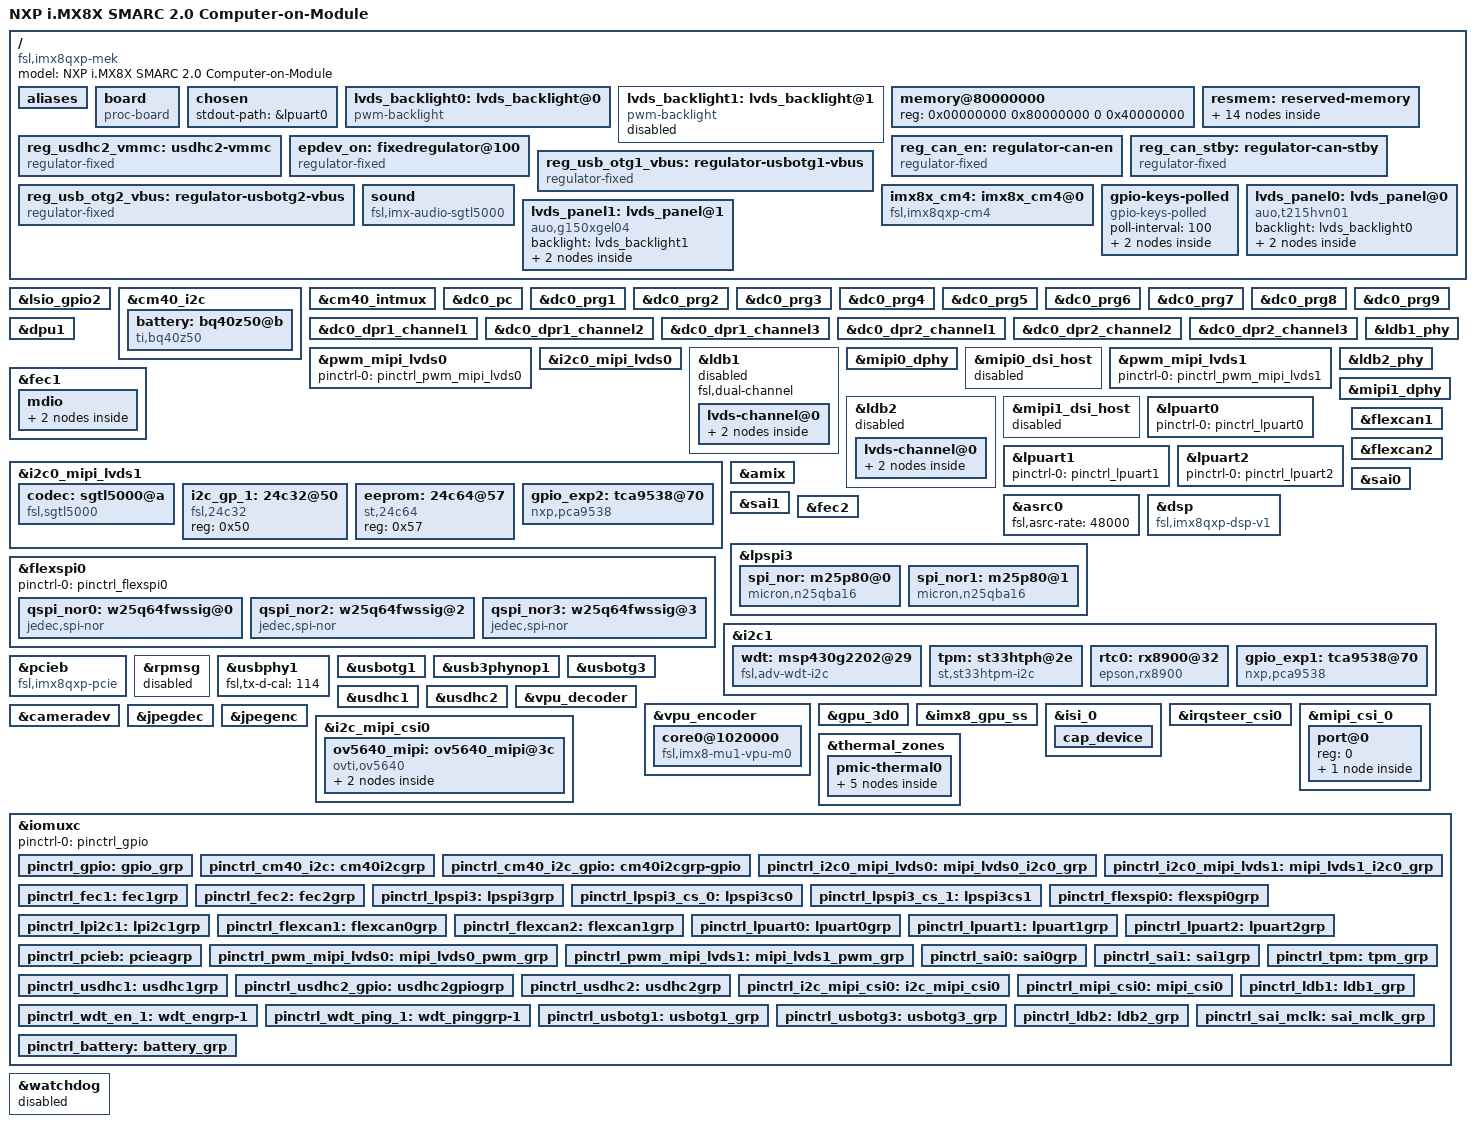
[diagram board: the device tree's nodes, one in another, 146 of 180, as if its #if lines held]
// SPDX-License-Identifier: GPL-2.0+
/*
 * Copyright 2017-2020 Advantech
 */

/dts-v1/;

#include "imx8qxp.dtsi"
#include <dt-bindings/usb/pd.h>

/* Definitions */
#define ROM_DB5901
#define SDHC_LOW_SPEED_ONLY
#define ROM_DB5901_I2S_CN3

/* LVDS Panel : only choose one!
 *   LVDS_AUO_7, LVDS_CHIMEI_15, LVDS_AUO_215
 */
#define LVDS_AUO_7

#ifdef LVDS_AUO_215
  #define LVDS_DUAL_CHANNEL
#endif
/*************************** based on imx8x-mek.dtsi *****************************/

/ {
	model = "NXP i.MX8X SMARC 2.0 Computer-on-Module";
	compatible = "fsl,imx8qxp-mek", "fsl,imx8qxp";

	aliases {
		rtc0 = &rtc0;
		rtc1 = &rtc;
	};

	board {
		compatible = "proc-board";
		board-type = "ROM-5620 A1";
		board-cpu = "IMX8X";
	};

	aliases {
		i2c0 = &i2c_mipi_csi0;
		i2c1 = &cm40_i2c;
		i2c2 = &i2c0_mipi_lvds0;
		i2c3 = &i2c0_mipi_lvds1;
		i2c4 = &i2c1;
	};

	chosen {
		stdout-path = &lpuart0;
	};

	lvds_backlight0: lvds_backlight@0 {
		compatible = "pwm-backlight";
		pwms = <&pwm_mipi_lvds0 0 5000000>;

		brightness-levels = < 0  1  2  3  4  5  6  7  8  9
				     10 11 12 13 14 15 16 17 18 19
				     20 21 22 23 24 25 26 27 28 29
				     30 31 32 33 34 35 36 37 38 39
				     40 41 42 43 44 45 46 47 48 49
				     50 51 52 53 54 55 56 57 58 59
				     60 61 62 63 64 65 66 67 68 69
				     70 71 72 73 74 75 76 77 78 79
				     80 81 82 83 84 85 86 87 88 89
				     90 91 92 93 94 95 96 97 98 99
				    100>;
		default-brightness-level = <80>;
	};

	lvds_backlight1: lvds_backlight@1 {
		compatible = "pwm-backlight";
		pwms = <&pwm_mipi_lvds1 0 5000000>;

		brightness-levels = < 0  1  2  3  4  5  6  7  8  9
				     10 11 12 13 14 15 16 17 18 19
				     20 21 22 23 24 25 26 27 28 29
				     30 31 32 33 34 35 36 37 38 39
				     40 41 42 43 44 45 46 47 48 49
				     50 51 52 53 54 55 56 57 58 59
				     60 61 62 63 64 65 66 67 68 69
				     70 71 72 73 74 75 76 77 78 79
				     80 81 82 83 84 85 86 87 88 89
				     90 91 92 93 94 95 96 97 98 99
				    100>;
		default-brightness-level = <80>;
	};

	memory@80000000 {
		device_type = "memory";
		reg = <0x00000000 0x80000000 0 0x40000000>;
	};

	resmem: reserved-memory {
		#address-cells = <2>;
		#size-cells = <2>;
		ranges;

		/*
		 * 0x8800_0000 ~ 0x8FFF_FFFF is reserved for M4
		 * Shouldn't be used at A core and Linux side.
		 *
		 */
		m4_reserved: m4@0x88000000 {
			no-map;
			reg = <0 0x88000000 0 0x8000000>;
		};

		rpmsg_reserved: rpmsg@0x90000000 {
			no-map;
			reg = <0 0x90200000 0 0x200000>;
		};

		decoder_boot: decoder-boot@84000000 {
			reg = <0 0x84000000 0 0x2000000>;
			no-map;
		};

		encoder_boot: encoder-boot@86000000 {
			reg = <0 0x86000000 0 0x200000>;
			no-map;
		};

		decoder_rpc: decoder-rpc@0x92000000 {
			reg = <0 0x92000000 0 0x200000>;
			no-map;
		};

		encoder_rpc: encoder-rpc@0x92200000 {
			reg = <0 0x92200000 0 0x200000>;
			no-map;
		};
		encoder_reserved: encoder_reserved@94400000 {
			no-map;
			reg = <0 0x94400000 0 0x800000>;
		};
		/* global autoconfigured region for contiguous allocations */
		linux,cma {
			compatible = "shared-dma-pool";
			reusable;
			size = <0 0x3c000000>;
			alloc-ranges = <0 0x96000000 0 0x3c000000>;
			linux,cma-default;
		};
	};

	/* SDIO_PWR_EN */
	reg_usdhc2_vmmc: usdhc2-vmmc {
		compatible = "regulator-fixed";
		regulator-name = "SD1_SPWR";
		regulator-min-microvolt = <3000000>;
		regulator-max-microvolt = <3000000>;
		gpio = <&lsio_gpio4 19 GPIO_ACTIVE_HIGH>;
		off-on-delay-us = <3480>;
		enable-active-high;
	};

	/* M2_SDIO_RST# */
	epdev_on: fixedregulator@100 {
		compatible = "regulator-fixed";
		regulator-min-microvolt = <3300000>;
		regulator-max-microvolt = <3300000>;
		regulator-name = "epdev_on";
		gpio = <&gpio_exp2 4 GPIO_ACTIVE_HIGH>;
		enable-active-high;
	};

	reg_can_en: regulator-can-en {
		compatible = "regulator-fixed";
		regulator-name = "can-en";
		regulator-min-microvolt = <3300000>;
		regulator-max-microvolt = <3300000>;
		enable-active-high;
	};

	reg_can_stby: regulator-can-stby {
		compatible = "regulator-fixed";
		regulator-name = "can-stby";
		regulator-min-microvolt = <3300000>;
		regulator-max-microvolt = <3300000>;
		enable-active-high;
		vin-supply = <&reg_can_en>;
	};

	/* USB0_OTG_EN_OC# */
	reg_usb_otg1_vbus: regulator-usbotg1-vbus {
		compatible = "regulator-fixed";
		regulator-name = "usb_otg1_vbus";
		regulator-min-microvolt = <5000000>;
		regulator-max-microvolt = <5000000>;
		gpio = <&lsio_gpio4 3 GPIO_ACTIVE_LOW>;
		enable-active-high;
	};

	/* USB1_EN_OC# */
	reg_usb_otg2_vbus: regulator-usbotg2-vbus {
		compatible = "regulator-fixed";
		regulator-name = "usb_otg2_vbus";
		regulator-min-microvolt = <3300000>;
		regulator-max-microvolt = <3300000>;
		gpio = <&lsio_gpio4 5 GPIO_ACTIVE_HIGH>;
		enable-active-low;
	};

#ifdef ROM_DB5901
	sound: sound {
		compatible = "fsl,imx-audio-sgtl5000";
		model = "sgtl5000";
#ifdef ROM_DB5901_I2S_CN3
		ssi-controller = <&sai1>;
#else
		ssi-controller = <&sai0>;
#endif
		audio-codec = <&codec>;
		no-audmux;
		audio-routing =
			"MIC_IN", "Mic Jack",
			"Mic Jack", "Mic Bias",
			"Headphone Jack", "HP_OUT";
	};
#endif

	imx8x_cm4: imx8x_cm4@0 {
		compatible = "fsl,imx8qxp-cm4";
		rsc-da = <0x90000000>;
		mbox-names = "tx", "rx", "rxdb";
		mboxes = <&lsio_mu5 0 1
			  &lsio_mu5 1 1
			  &lsio_mu5 3 1>;
		mub-partition = <3>;
		memory-region = <&vdev0vring0>, <&vdev0vring1>, <&vdevbuffer>,
				<&vdev1vring0>, <&vdev1vring1>;
		core-index = <0>;
		core-id = <IMX_SC_R_M4_0_PID0>;
		status = "okay";
		power-domains = <&pd IMX_SC_R_M4_0_PID0>,
				<&pd IMX_SC_R_M4_0_MU_1A>;
	};

	reserved-memory {
		#address-cells = <2>;
		#size-cells = <2>;
		ranges;

		vdev0vring0: vdev0vring0@90000000 {
                        compatible = "shared-dma-pool";
			reg = <0 0x90000000 0 0x8000>;
			no-map;
		};

		vdev0vring1: vdev0vring1@90008000 {
                        compatible = "shared-dma-pool";
			reg = <0 0x90008000 0 0x8000>;
			no-map;
		};

		vdev1vring0: vdev1vring0@90010000 {
                        compatible = "shared-dma-pool";
			reg = <0 0x90010000 0 0x8000>;
			no-map;
		};

		vdev1vring1: vdev1vring1@90018000 {
                        compatible = "shared-dma-pool";
			reg = <0 0x90018000 0 0x8000>;
			no-map;
		};

		rsc-table {
			reg = <0 0x900ff000 0 0x1000>;
			no-map;
		};

		vdevbuffer: vdevbuffer {
                        compatible = "shared-dma-pool";
			reg = <0 0x90400000 0 0x100000>;
			no-map;
		};
	};
        gpio-keys-polled {
                compatible = "gpio-keys-polled";
                #address-cells = <1>;
                #size-cells = <0>;
                poll-interval = <100>;

                lid@1 {
                        label = "LID KEY";
                        gpios = <&gpio_exp1 6 GPIO_ACTIVE_LOW>;
                        linux,input-type = <EV_KEY>; //EV_KEY 1, EV_PWR 22
                        linux,code = <KEY_SUSPEND>; //KEY_SUSPEND 205, KEY_POWER 116
                };

                sleep@2 {
                        label = "SLEEP KEY";
                        gpios = <&gpio_exp1 7 GPIO_ACTIVE_LOW>;
                        linux,input-type = <EV_KEY>; //EV_KEY 1, EV_PWR 22
                        linux,code = <KEY_SUSPEND>; //KEY_SUSPEND 205, KEY_POWER 116
                };
        };

	lvds_panel0: lvds_panel@0 {
#ifdef LVDS_AUO_215 /* Dual channel panel */
		compatible = "auo,t215hvn01";
#elif defined(LVDS_CHIMEI_15)
		compatible = "auo,g150xgel04";
#else /* LVDS_AUO_7 */
		compatible = "auo,g070vvn01";
#endif
		backlight = <&lvds_backlight0>;

		port {
			panel_lvds_in0: endpoint {
				remote-endpoint = <&lvds_out0>;
			};
		};
	};

	lvds_panel1: lvds_panel@1 {
#ifdef LVDS_CHIMEI_15
		compatible = "auo,g150xgel04";
#else /* LVDS_AUO_7 */
		compatible = "auo,g070vvn01";
#endif
		backlight = <&lvds_backlight1>;

		port {
			panel_lvds_in1: endpoint {
				remote-endpoint = <&lvds_out1>;
			};
		};
	};
};

&lsio_gpio2 {
	pad-wakeup-num = <1>;
	pad-wakeup = <IMX8QXP_SCU_GPIO0_00 6 3>;
};

&cm40_i2c {
	#address-cells = <1>;
	#size-cells = <0>;
	clock-frequency = <100000>;
	pinctrl-names = "default", "gpio";
	pinctrl-0 = <&pinctrl_cm40_i2c>;
	pinctrl-1 = <&pinctrl_cm40_i2c_gpio>;
	scl-gpios = <&lsio_gpio1 10 GPIO_ACTIVE_HIGH>;
	sda-gpios = <&lsio_gpio1 9 GPIO_ACTIVE_HIGH>;
	status = "okay";

#ifdef ROM_DB5901
	battery: bq40z50@b {
		compatible = "ti,bq40z50";
		reg = <0x0b>;
		pinctrl-names = "default";
		pinctrl-0 = <&pinctrl_battery>;
	};
#endif
};

&cm40_intmux {
	status = "okay";
};

&dc0_pc {
	status = "okay";
};

&dc0_prg1 {
	status = "okay";
};

&dc0_prg2 {
	status = "okay";

};

&dc0_prg3 {
	status = "okay";
};

&dc0_prg4 {
	status = "okay";
};

&dc0_prg5 {
	status = "okay";
};

&dc0_prg6 {
	status = "okay";
};

&dc0_prg7 {
	status = "okay";
};

&dc0_prg8 {
	status = "okay";
};

&dc0_prg9 {
	status = "okay";
};

&dc0_dpr1_channel1 {
	status = "okay";
};

&dc0_dpr1_channel2 {
	status = "okay";
};

&dc0_dpr1_channel3 {
	status = "okay";
};

&dc0_dpr2_channel1 {
	status = "okay";
};

&dc0_dpr2_channel2 {
	status = "okay";
};

&dc0_dpr2_channel3 {
	status = "okay";
};

&dpu1 {
	status = "okay";
};

&pwm_mipi_lvds0 {
	pinctrl-names = "default";
	pinctrl-0 = <&pinctrl_pwm_mipi_lvds0>;
	status = "okay";
};

&i2c0_mipi_lvds0 {
	#address-cells = <1>;
	#size-cells = <0>;
	pinctrl-names = "default";
	pinctrl-0 = <&pinctrl_i2c0_mipi_lvds0>;
	clock-frequency = <100000>;
	status = "okay";
};

&ldb1_phy {
	status = "okay";
};

&ldb1 {
#ifdef LVDS_SINGLE_1
	status = "disabled";
#else
	status = "okay";
#endif

#ifdef LVDS_DUAL_CHANNEL
	fsl,dual-channel;
#endif
	lvds-channel@0 {
		fsl,data-mapping = "spwg";
		fsl,data-width = <24>;
		status = "okay";

		port@1 {
			reg = <1>;
			lvds_out0: endpoint {
				remote-endpoint = <&panel_lvds_in0>;
			};
		};
	};
};

&mipi0_dphy {
	status = "okay";
};

&mipi0_dsi_host {
	status = "disabled";
};

&lvds_backlight1 {
	pinctrl-names = "default";
	pinctrl-0 = <&pinctrl_ldb2>;
	lvds-vcc-enable = <&lsio_gpio0 12 1>;
	lvds-bkl-enable = <&lsio_gpio3 8 1>;
#if defined(LVDS_SINGLE_0)
	status = "disabled";
#elif defined(LVDS_SINGLE_1)
	status = "okay";
#else
	skip-gpios-init;
	status = "okay";
#endif
};

&pwm_mipi_lvds1 {
	pinctrl-names = "default";
	pinctrl-0 = <&pinctrl_pwm_mipi_lvds1>;
	status = "okay";
};

&fec1 {
	pinctrl-names = "default";
	pinctrl-0 = <&pinctrl_fec1>;
	phy-mode = "rgmii-txid";
	phy-handle = <&ethphy0>;
	fsl,magic-packet;
	nvmem-cells = <&fec_mac0>;
	nvmem-cell-names = "mac-address";
	fsl,rgmii_rxc_dly;
	status = "okay";

	mdio {
		#address-cells = <1>;
		#size-cells = <0>;

		ethphy0: ethernet-phy@0 {
			compatible = "ethernet-phy-ieee802.3-c22";
			reg = <4>;
			at803x,eee-disabled;
			at803x,vddio-1p8v;
		};

		ethphy1: ethernet-phy@1 {
			compatible = "ethernet-phy-ieee802.3-c22";
			reg = <6>;
			at803x,eee-disabled;
			at803x,vddio-1p8v;
		};
	};
};

&i2c0_mipi_lvds1 {
	#address-cells = <1>;
	#size-cells = <0>;
	pinctrl-names = "default";
	pinctrl-0 = <&pinctrl_i2c0_mipi_lvds1>;
	clock-frequency = <100000>;
	status = "okay";

#ifdef ROM_DB5901
	codec: sgtl5000@a {
		compatible = "fsl,sgtl5000";
		reg = <0x0a>;
		clocks = <&mclkout0_lpcg 0>;
		clock-names = "mclk";
		pinctrl-names = "default";
		pinctrl-0 = <&pinctrl_sai_mclk>;
		assigned-clocks = <&clk IMX_SC_R_AUDIO_PLL_0 IMX_SC_PM_CLK_PLL>,
					<&clk IMX_SC_R_AUDIO_PLL_0 IMX_SC_PM_CLK_SLV_BUS>,
					<&clk IMX_SC_R_AUDIO_PLL_0 IMX_SC_PM_CLK_MST_BUS>,
					<&mclkout0_lpcg 0>;
		assigned-clock-rates = <786432000>, <49152000>, <24000000>, <24000000>;
	};

	i2c_gp_1: 24c32@50 {
		compatible = "fsl,24c32";
		reg = <0x50>;
	};

	eeprom: 24c64@57 {
		compatible = "st,24c64";
		reg = <0x57>;
	};

	gpio_exp2: tca9538@70 {
		compatible = "nxp,pca9538";
		reg = <0x70>;
		gpio-controller;
		#gpio-cells = <2>;
	};
#endif
};

&ldb2_phy {
	status = "okay";
};

&ldb2 {
#ifdef LVDS_DUAL_CHANNEL
	status = "disabled";
#elif defined(LVDS_SINGLE_0)
	status = "disabled";
#elif defined(LVDS_SINGLE_1)
	status = "okay";
#else
	status = "okay";
#endif
	lvds-channel@0 {
		fsl,data-mapping = "spwg";
		fsl,data-width = <24>;
		status = "okay";

		port@1 {
			reg = <1>;
			lvds_out1: endpoint {
				remote-endpoint = <&panel_lvds_in1>;
			};
		};
	};
};

&mipi1_dphy {
	status = "okay";
};

&mipi1_dsi_host {
	status = "disabled";
};

&lpuart0 {
	pinctrl-names = "default";
	pinctrl-0 = <&pinctrl_lpuart0>;
	status = "okay";
};

&lpuart1 {
	pinctrl-names = "default";
	pinctrl-0 = <&pinctrl_lpuart1>;
	status = "okay";
};

&lpuart2 {
	pinctrl-names = "default";
	pinctrl-0 = <&pinctrl_lpuart2>;
	status = "okay";
};

&flexcan1 {
	pinctrl-names = "default";
	pinctrl-0 = <&pinctrl_flexcan1>;
	xceiver-supply = <&reg_can_stby>;
	status = "okay";
};

&flexcan2 {
	pinctrl-names = "default";
	pinctrl-0 = <&pinctrl_flexcan2>;
	xceiver-supply = <&reg_can_stby>;
	status = "okay";
};

&amix {
	status = "okay";
};

&asrc0 {
	fsl,asrc-rate  = <48000>;
	status = "okay";
};

&dsp {
	compatible = "fsl,imx8qxp-dsp-v1";
	status = "okay";
};

&sai0 {
	assigned-clocks = <&clk IMX_SC_R_AUDIO_PLL_0 IMX_SC_PM_CLK_PLL>,
			<&clk IMX_SC_R_AUDIO_PLL_0 IMX_SC_PM_CLK_SLV_BUS>,
			<&clk IMX_SC_R_AUDIO_PLL_0 IMX_SC_PM_CLK_MST_BUS>,
			<&sai0_lpcg 0>;
	assigned-clock-rates = <786432000>, <49152000>, <24000000>, <49152000>;
	pinctrl-names = "default";
	pinctrl-0 = <&pinctrl_sai0>;
	status = "okay";
};

&sai1 {
	assigned-clocks = <&clk IMX_SC_R_AUDIO_PLL_0 IMX_SC_PM_CLK_PLL>,
			<&clk IMX_SC_R_AUDIO_PLL_0 IMX_SC_PM_CLK_SLV_BUS>,
			<&clk IMX_SC_R_AUDIO_PLL_0 IMX_SC_PM_CLK_MST_BUS>,
			<&sai1_lpcg 0>; /* FIXME: should be sai1, original code is 0 */
	assigned-clock-rates = <786432000>, <49152000>, <24000000>, <49152000>;
	pinctrl-names = "default";
	pinctrl-0 = <&pinctrl_sai1>;
	status = "okay";
};

&fec2 {
	pinctrl-names = "default";
	pinctrl-0 = <&pinctrl_fec2>;
	phy-mode = "rgmii-txid";
	phy-handle = <&ethphy1>;
	fsl,magic-packet;
	nvmem-cells = <&fec_mac1>;
	nvmem-cell-names = "mac-address";
	fsl,rgmii_rxc_dly;
	status = "okay";
};

&lpspi3 {
	#address-cells = <1>;
	#size-cells = <0>;
	fsl,spi-num-chipselects = <2>;
	pinctrl-names = "default";
	pinctrl-0 = <&pinctrl_lpspi3 &pinctrl_lpspi3_cs_0 &pinctrl_lpspi3_cs_1>;
	cs-gpios = <&lsio_gpio0 16 GPIO_ACTIVE_LOW>, <&lsio_gpio1 19 GPIO_ACTIVE_LOW>;
	status = "okay";

#ifdef ROM_DB5901
	spi_nor: m25p80@0 {
		compatible = "micron,n25qba16";
		spi-max-frequency = <10000000>;
		reg = <0>;
	};

	spi_nor1: m25p80@1 {
		compatible = "micron,n25qba16";
		spi-max-frequency = <10000000>;
		reg = <1>;
	};
#endif
};

&flexspi0 {
	pinctrl-names = "default";
	pinctrl-0 = <&pinctrl_flexspi0>;
	status = "okay";

	qspi_nor0: w25q64fwssig@0 {
		reg = <0>;
		#address-cells = <1>;
		#size-cells = <1>;
		compatible = "jedec,spi-nor", "winbond,w25q64";
		spi-max-frequency = <29000000>;
	};
#if defined(ROM_DB5901)
	qspi_nor2: w25q64fwssig@2 {
		reg = <2>;
		#address-cells = <1>;
		#size-cells = <1>;
		compatible = "jedec,spi-nor", "winbond,w25q64";
		spi-max-frequency = <29000000>;
	};

	qspi_nor3: w25q64fwssig@3 {
		reg = <3>;
		#address-cells = <1>;
		#size-cells = <1>;
		compatible = "jedec,spi-nor", "winbond,w25q64";
		spi-max-frequency = <29000000>;
	};
#endif
};

&i2c1 {
	#address-cells = <1>;
	#size-cells = <0>;
	clock-frequency = <100000>;
	pinctrl-names = "default";
	pinctrl-0 = <&pinctrl_lpi2c1>;
	status = "okay";

	wdt: msp430g2202@29 {
		compatible = "fsl,adv-wdt-i2c";
		reg = <0x29>;
		pinctrl-names = "default";
		pinctrl-0 = <&pinctrl_wdt_en_1 &pinctrl_wdt_ping_1>;
		wdt-en = <&lsio_gpio1 13 0>;
		wdt-ping = <&lsio_gpio1 14 0>;
		status = "okay";
	};

	tpm: st33htph@2e {
		compatible = "st,st33htpm-i2c";
		reg= <0x2e>;
		pinctrl-names = "default";
		pinctrl-0 = <&pinctrl_tpm>;
		status = "okay";
	};

	rtc0: rx8900@32 {
		compatible = "epson,rx8900";
		reg = <0x32>;
		epson,vdet-disable;
		trickle-diode-disable;
		status = "okay";
	};

	gpio_exp1: tca9538@70 {
		compatible = "nxp,pca9538";
		reg = <0x70>;
		gpio-controller;
		#gpio-cells = <2>;
	};
};

&pcieb{
	compatible = "fsl,imx8qxp-pcie","snps,dw-pcie";
	pinctrl-names = "default";
	pinctrl-0 = <&pinctrl_pcieb>;
	//disable-gpio = <&gpio_exp2 0 GPIO_ACTIVE_LOW>; /* W_DISABLE1# */
	reset-gpio = <&lsio_gpio4 0 GPIO_ACTIVE_LOW>;
	ext_osc = <1>;
	status = "okay";
};

&rpmsg{
	/*
	 * 64K for one rpmsg instance:
	 */
	vdev-nums = <2>;
	reg = <0x0 0x90000000 0x0 0x20000>;
	memory-region = <&vdevbuffer>;
	status = "disabled";
};

&usbphy1 {
	fsl,tx-d-cal = <114>;
	status = "okay";
};

&usbotg1 {
	vbus-supply = <&reg_usb_otg1_vbus>;
	pinctrl-names = "default";
	pinctrl-0 = <&pinctrl_usbotg1>;
	dr_mode = "otg";
	srp-disable;
	hnp-disable;
	adp-disable;
	power-active-high;
	disable-over-current;
	status = "okay";
};

&usb3phynop1 {
	status = "okay";
};

&usbotg3 {
	vbus-supply = <&reg_usb_otg2_vbus>;
	pinctrl-names = "default";
	pinctrl-0 = <&pinctrl_usbotg3>;
	dr_mode = "host";
	status = "okay";
};

&usdhc1 {
	pinctrl-names = "default", "state_100mhz", "state_200mhz";
	pinctrl-0 = <&pinctrl_usdhc1>;
	pinctrl-1 = <&pinctrl_usdhc1>;
	pinctrl-2 = <&pinctrl_usdhc1>;
	bus-width = <8>;
	no-sd;
	no-sdio;
	non-removable;
	cqe-disabled;
	status = "okay";
};

&usdhc2 {
	pinctrl-names = "default", "state_100mhz", "state_200mhz";
	pinctrl-0 = <&pinctrl_usdhc2>, <&pinctrl_usdhc2_gpio>;
	pinctrl-1 = <&pinctrl_usdhc2>, <&pinctrl_usdhc2_gpio>;
	pinctrl-2 = <&pinctrl_usdhc2>, <&pinctrl_usdhc2_gpio>;
	bus-width = <4>;
	vmmc-supply = <&reg_usdhc2_vmmc>;
	cd-gpios = <&lsio_gpio4 22 GPIO_ACTIVE_LOW>;
	wp-gpios = <&lsio_gpio4 21 GPIO_ACTIVE_HIGH>;
#ifdef SDHC_LOW_SPEED_ONLY
	no-1-8-v;
#endif
	status = "okay";
};

&vpu_decoder {
	boot-region = <&decoder_boot>;
	rpc-region = <&decoder_rpc>;
	reg-csr = <0x2d040000>;
	core_type = <1>;
	status = "okay";
};

&vpu_encoder {
	boot-region = <&encoder_boot>;
	rpc-region = <&encoder_rpc>;
	reserved-region = <&encoder_reserved>;
	reg-rpc-system = <0x40000000>;
	resolution-max = <1920 1920>;
	mbox-names = "enc1_tx0", "enc1_tx1", "enc1_rx";
	mboxes = <&mu1_m0 0 0
		  &mu1_m0 0 1
		  &mu1_m0 1 0>;
	status = "okay";

	core0@1020000 {
		compatible = "fsl,imx8-mu1-vpu-m0";
		reg = <0x1020000 0x20000>;
		reg-csr = <0x1050000 0x10000>;
		interrupts = <GIC_SPI 470 IRQ_TYPE_LEVEL_HIGH>;
		fsl,vpu_ap_mu_id = <17>;
		fw-buf-size = <0x200000>;
		rpc-buf-size = <0x80000>;
		print-buf-size = <0x80000>;
	};
};

&lvds_backlight0 {
	pinctrl-names = "default";
	pinctrl-0 = <&pinctrl_ldb1>;
	lvds-vcc-enable = <&lsio_gpio3 13 1>;
	lvds-bkl-enable = <&lsio_gpio3 7 1>;
#if defined(LVDS_SINGLE_0)
	status = "okay";
#elif defined(LVDS_SINGLE_1)
	status = "disabled";
#else
	skip-gpios-init;
	status = "okay";
#endif
};

&gpu_3d0 {
	status = "okay";
};

&imx8_gpu_ss {
	status = "okay";
};

&isi_0 {
	status = "okay";

	cap_device {
		status = "okay";
	};
};

&irqsteer_csi0 {
	status = "okay";
};

&mipi_csi_0 {
	#address-cells = <1>;
	#size-cells = <0>;
	status = "okay";

	/* Camera 0  MIPI CSI-2 (CSIS0) */
	port@0 {
		reg = <0>;
		mipi_csi0_ep: endpoint {
			remote-endpoint = <&ov5640_mipi_ep>;
			data-lanes = <1 2>;
		};
	};
};

&cameradev {
	status = "okay";
};

&jpegdec {
	status = "okay";
};

&jpegenc {
	status = "okay";
};

&i2c_mipi_csi0 {
	#address-cells = <1>;
	#size-cells = <0>;
	pinctrl-names = "default";
	pinctrl-0 = <&pinctrl_i2c_mipi_csi0>;
	clock-frequency = <100000>;
	status = "okay";

	ov5640_mipi: ov5640_mipi@3c {
		compatible = "ovti,ov5640";
		reg = <0x3c>;
		pinctrl-names = "default";
		pinctrl-0 = <&pinctrl_mipi_csi0>;
		clocks = <&xtal24m>;
		clock-names = "xclk";
		csi_id = <0>;
		powerdown-gpios = <&lsio_gpio1 3 GPIO_ACTIVE_HIGH>;
		reset-gpios = <&lsio_gpio1 1 GPIO_ACTIVE_LOW>;
		mclk = <24000000>;
		mclk_source = <0>;
		mipi_csi;
		status = "okay";

		port {
			ov5640_mipi_ep: endpoint {
				remote-endpoint = <&mipi_csi0_ep>;
 				data-lanes = <1 2>;
				clock-lanes = <0>;
			};
		};
	};
};

&thermal_zones {
	pmic-thermal0 {
		polling-delay-passive = <250>;
		polling-delay = <2000>;
		thermal-sensors = <&tsens 497>;
		trips {
			pmic_alert0: trip0 {
				temperature = <110000>;
				hysteresis = <2000>;
				type = "passive";
			};
			pmic_crit0: trip1 {
				temperature = <125000>;
				hysteresis = <2000>;
				type = "critical";
			};
		};
		cooling-maps {
			map0 {
				trip = <&pmic_alert0>;
				cooling-device =
					<&A35_0 THERMAL_NO_LIMIT THERMAL_NO_LIMIT>,
					<&A35_1 THERMAL_NO_LIMIT THERMAL_NO_LIMIT>,
					<&A35_2 THERMAL_NO_LIMIT THERMAL_NO_LIMIT>,
					<&A35_3 THERMAL_NO_LIMIT THERMAL_NO_LIMIT>;
			};
		};
	};
};

&iomuxc {
	pinctrl-names = "default";
	pinctrl-0 = <&pinctrl_gpio>;

	pinctrl_gpio: gpio_grp {
		fsl,pins = <
			IMX8QXP_SPI2_CS0_LSIO_GPIO1_IO00	0x06000021	/* GPIO0 */
			//IMX8QXP_SPI2_SCK_LSIO_GPIO1_IO03	0x06000021	/* GPIO1 */
			IMX8QXP_SPI2_SDI_LSIO_GPIO1_IO02	0x06000021	/* GPIO2 */
			//IMX8QXP_SPI2_SDO_LSIO_GPIO1_IO01	0x06000021	/* GPIO3 */
			IMX8QXP_SPI0_CS0_LSIO_GPIO1_IO08	0x06000021	/* GPIO4 */
			IMX8QXP_SPI0_SCK_LSIO_GPIO1_IO04	0x06000021	/* GPIO5 */
			IMX8QXP_SPI0_SDI_LSIO_GPIO1_IO05	0x06000021	/* GPIO6 */
			IMX8QXP_MCLK_IN0_LSIO_GPIO0_IO19	0x06000021	/* GPIO7 */
			IMX8QXP_SPI0_SDO_LSIO_GPIO1_IO06	0x06000021	/* GPIO8 */
			IMX8QXP_CSI_PCLK_LSIO_GPIO3_IO00	0x06000021	/* GPIO9 */
			IMX8QXP_CSI_MCLK_LSIO_GPIO3_IO01	0x06000021	/* GPIO10 */
			IMX8QXP_CSI_EN_LSIO_GPIO3_IO02	0x06000021	/* GPIO11 */
			IMX8QXP_SAI0_RXD_LSIO_GPIO0_IO27	0x06000021	/* DEBUG_UART_SEL */
			IMX8QXP_USDHC1_VSELECT_LSIO_GPIO4_IO20	0x06000021	/* DEBUG_UART_SEL */
		>;
	};

	pinctrl_cm40_i2c: cm40i2cgrp {
		fsl,pins = <
			IMX8QXP_ADC_IN1_M40_I2C0_SDA                            0x0600004c
			IMX8QXP_ADC_IN0_M40_I2C0_SCL                            0x0600004c
		>;
	};

	pinctrl_cm40_i2c_gpio: cm40i2cgrp-gpio {
		fsl,pins = <
			IMX8QXP_ADC_IN1_LSIO_GPIO1_IO09		0xc600004c
			IMX8QXP_ADC_IN0_LSIO_GPIO1_IO10		0xc600004c
		>;
	};

	pinctrl_i2c0_mipi_lvds0: mipi_lvds0_i2c0_grp {
		fsl,pins = <
			IMX8QXP_MIPI_DSI0_I2C0_SCL_MIPI_DSI0_I2C0_SCL		0xc6000020
			IMX8QXP_MIPI_DSI0_I2C0_SDA_MIPI_DSI0_I2C0_SDA		0xc6000020
		>;
	};

	pinctrl_i2c0_mipi_lvds1: mipi_lvds1_i2c0_grp {
		fsl,pins = <
			IMX8QXP_MIPI_DSI1_I2C0_SCL_MIPI_DSI1_I2C0_SCL		0xc6000020
			IMX8QXP_MIPI_DSI1_I2C0_SDA_MIPI_DSI1_I2C0_SDA		0xc6000020
		>;
	};

	pinctrl_fec1: fec1grp {
		fsl,pins = <
			IMX8QXP_ENET0_MDC_CONN_ENET0_MDC			0x06000020
			IMX8QXP_ENET0_MDIO_CONN_ENET0_MDIO			0x06000020
			IMX8QXP_ENET0_RGMII_TX_CTL_CONN_ENET0_RGMII_TX_CTL	0x06000020
			IMX8QXP_ENET0_RGMII_TXC_CONN_ENET0_RGMII_TXC		0x06000020
			IMX8QXP_ENET0_RGMII_TXD0_CONN_ENET0_RGMII_TXD0		0x06000020
			IMX8QXP_ENET0_RGMII_TXD1_CONN_ENET0_RGMII_TXD1		0x06000020
			IMX8QXP_ENET0_RGMII_TXD2_CONN_ENET0_RGMII_TXD2		0x06000020
			IMX8QXP_ENET0_RGMII_TXD3_CONN_ENET0_RGMII_TXD3		0x06000020
			IMX8QXP_ENET0_RGMII_RXC_CONN_ENET0_RGMII_RXC		0x06000020
			IMX8QXP_ENET0_RGMII_RX_CTL_CONN_ENET0_RGMII_RX_CTL	0x06000020
			IMX8QXP_ENET0_RGMII_RXD0_CONN_ENET0_RGMII_RXD0		0x06000020
			IMX8QXP_ENET0_RGMII_RXD1_CONN_ENET0_RGMII_RXD1		0x06000020
			IMX8QXP_ENET0_RGMII_RXD2_CONN_ENET0_RGMII_RXD2		0x06000020
			IMX8QXP_ENET0_RGMII_RXD3_CONN_ENET0_RGMII_RXD3		0x06000020
			IMX8QXP_ENET0_REFCLK_125M_25M_LSIO_GPIO5_IO09		0x06000021	/* ENET0_INT */
		>;
	};

	pinctrl_fec2: fec2grp {
		fsl,pins = <
			IMX8QXP_ESAI0_SCKR_CONN_ENET1_RGMII_TX_CTL	0x00000060
			IMX8QXP_ESAI0_FSR_CONN_ENET1_RGMII_TXC		0x00000060
			IMX8QXP_ESAI0_TX4_RX1_CONN_ENET1_RGMII_TXD0	0x00000060
			IMX8QXP_ESAI0_TX5_RX0_CONN_ENET1_RGMII_TXD1	0x00000060
			IMX8QXP_ESAI0_FST_CONN_ENET1_RGMII_TXD2		0x00000060
			IMX8QXP_ESAI0_SCKT_CONN_ENET1_RGMII_TXD3	0x00000060
			IMX8QXP_ESAI0_TX0_CONN_ENET1_RGMII_RXC		0x00000060
			IMX8QXP_SPDIF0_TX_CONN_ENET1_RGMII_RX_CTL	0x00000060
			IMX8QXP_SPDIF0_RX_CONN_ENET1_RGMII_RXD0		0x00000060
			IMX8QXP_ESAI0_TX3_RX2_CONN_ENET1_RGMII_RXD1	0x00000060
			IMX8QXP_ESAI0_TX2_RX3_CONN_ENET1_RGMII_RXD2	0x00000060
			IMX8QXP_ESAI0_TX1_CONN_ENET1_RGMII_RXD3		0x00000060
			IMX8QXP_PCIE_CTRL0_CLKREQ_B_LSIO_GPIO4_IO01		0x06000021	/* ENET1_INT */
		>;
	};

	pinctrl_lpspi3: lpspi3grp {
		fsl,pins = <
			IMX8QXP_SPI3_SCK_ADMA_SPI3_SCK		0x0600004c
			IMX8QXP_SPI3_SDO_ADMA_SPI3_SDO		0x0600004c
			IMX8QXP_SPI3_SDI_ADMA_SPI3_SDI		0x0600004c
		>;
	};

	pinctrl_lpspi3_cs_0: lpspi3cs0 {
		fsl,pins = <
			IMX8QXP_SPI3_CS0_LSIO_GPIO0_IO16		0x21
		>;
	};

	pinctrl_lpspi3_cs_1: lpspi3cs1 {
		fsl,pins = <
			IMX8QXP_FLEXCAN2_RX_LSIO_GPIO1_IO19		0x21
		>;
	};

	pinctrl_flexspi0: flexspi0grp {
		fsl,pins = <
			IMX8QXP_QSPI0A_DATA0_LSIO_QSPI0A_DATA0     0x06000021
			IMX8QXP_QSPI0A_DATA1_LSIO_QSPI0A_DATA1     0x06000021
			IMX8QXP_QSPI0A_DATA2_LSIO_QSPI0A_DATA2     0x06000021
			IMX8QXP_QSPI0A_DATA3_LSIO_QSPI0A_DATA3     0x06000021
			IMX8QXP_QSPI0A_SS0_B_LSIO_QSPI0A_SS0_B     0x06000021
			IMX8QXP_QSPI0A_SCLK_LSIO_QSPI0A_SCLK       0x06000021
#if defined(ROM_DB5901)
			IMX8QXP_QSPI0B_SCLK_LSIO_QSPI0B_SCLK       0x06000021
			IMX8QXP_QSPI0B_DATA0_LSIO_QSPI0B_DATA0     0x06000021
			IMX8QXP_QSPI0B_DATA1_LSIO_QSPI0B_DATA1     0x06000021
			IMX8QXP_QSPI0B_DATA2_LSIO_QSPI0B_DATA2     0x06000021
			IMX8QXP_QSPI0B_DATA3_LSIO_QSPI0B_DATA3     0x06000021
			IMX8QXP_QSPI0B_DQS_LSIO_QSPI0B_DQS         0x06000021
			IMX8QXP_QSPI0B_SS0_B_LSIO_QSPI0B_SS0_B     0x06000021
			IMX8QXP_QSPI0B_SS1_B_LSIO_QSPI0B_SS1_B     0x06000021
#endif
		>;
	};

	pinctrl_lpi2c1: lpi2c1grp {
		fsl,pins = <
			IMX8QXP_USB_SS3_TC1_ADMA_I2C1_SCL			0x06000021
			IMX8QXP_USB_SS3_TC3_ADMA_I2C1_SDA			0x06000021
		>;
	};

	pinctrl_flexcan1: flexcan0grp {
		fsl,pins = <
			IMX8QXP_FLEXCAN0_TX_ADMA_FLEXCAN0_TX            0x21
			IMX8QXP_FLEXCAN0_RX_ADMA_FLEXCAN0_RX            0x21
		>;
	};

	pinctrl_flexcan2: flexcan1grp {
		fsl,pins = <
			IMX8QXP_FLEXCAN1_TX_ADMA_FLEXCAN1_TX            0x21
			IMX8QXP_FLEXCAN1_RX_ADMA_FLEXCAN1_RX            0x21
			>;
	};

	pinctrl_lpuart0: lpuart0grp {
		fsl,pins = <
			IMX8QXP_UART0_RX_ADMA_UART0_RX				0x06000020
			IMX8QXP_UART0_TX_ADMA_UART0_TX				0x06000020
		>;
	};

	pinctrl_lpuart1: lpuart1grp {
		fsl,pins = <
			IMX8QXP_UART1_TX_ADMA_UART1_TX		0x06000020
			IMX8QXP_UART1_RX_ADMA_UART1_RX		0x06000020
			IMX8QXP_UART1_RTS_B_ADMA_UART1_RTS_B	0x06000020
			IMX8QXP_UART1_CTS_B_ADMA_UART1_CTS_B	0x06000020
		>;
	};

	pinctrl_lpuart2: lpuart2grp {
		fsl,pins = <
			IMX8QXP_UART2_TX_ADMA_UART2_TX		0x06000020
			IMX8QXP_UART2_RX_ADMA_UART2_RX		0x06000020
		>;
	};

	pinctrl_pcieb: pcieagrp{
		fsl,pins = <
			IMX8QXP_PCIE_CTRL0_PERST_B_LSIO_GPIO4_IO00		0x06000021
			IMX8QXP_PCIE_CTRL0_WAKE_B_LSIO_GPIO4_IO02		0x04000021
		>;
	};

	pinctrl_pwm_mipi_lvds0: mipi_lvds0_pwm_grp {
		fsl,pins = <
			IMX8QXP_MIPI_DSI0_GPIO0_00_MIPI_DSI0_PWM0_OUT		0x00000020
		>;
	};

	pinctrl_pwm_mipi_lvds1: mipi_lvds1_pwm_grp {
		fsl,pins = <
			IMX8QXP_MIPI_DSI1_GPIO0_00_MIPI_DSI1_PWM0_OUT		0x00000020
		>;
	};

	pinctrl_sai0: sai0grp {
		fsl,pins = <
			IMX8QXP_CSI_D01_ADMA_SAI0_RXD	0x06000040
			IMX8QXP_SAI0_TXC_ADMA_SAI0_TXC	0x06000040
			IMX8QXP_SAI0_TXFS_ADMA_SAI0_TXFS	0x06000040
			IMX8QXP_SAI0_TXD_ADMA_SAI0_TXD	0x06000040
		>;
	};

	pinctrl_sai1: sai1grp {
		fsl,pins = <
			IMX8QXP_SAI1_RXD_ADMA_SAI1_RXD     0x06000040
			IMX8QXP_SAI1_RXC_ADMA_SAI1_TXC     0x06000040
			IMX8QXP_SAI1_RXFS_ADMA_SAI1_TXFS   0x06000040
			IMX8QXP_SPI0_CS1_ADMA_SAI1_TXD     0x06000040
		>;
	};

	pinctrl_usdhc1: usdhc1grp {
		fsl,pins = <
			IMX8QXP_EMMC0_CLK_CONN_EMMC0_CLK			0x06000041
			IMX8QXP_EMMC0_CMD_CONN_EMMC0_CMD			0x00000021
			IMX8QXP_EMMC0_DATA0_CONN_EMMC0_DATA0			0x00000021
			IMX8QXP_EMMC0_DATA1_CONN_EMMC0_DATA1			0x00000021
			IMX8QXP_EMMC0_DATA2_CONN_EMMC0_DATA2			0x00000021
			IMX8QXP_EMMC0_DATA3_CONN_EMMC0_DATA3			0x00000021
			IMX8QXP_EMMC0_DATA4_CONN_EMMC0_DATA4			0x00000021
			IMX8QXP_EMMC0_DATA5_CONN_EMMC0_DATA5			0x00000021
			IMX8QXP_EMMC0_DATA6_CONN_EMMC0_DATA6			0x00000021
			IMX8QXP_EMMC0_DATA7_CONN_EMMC0_DATA7			0x00000021
			IMX8QXP_EMMC0_STROBE_CONN_EMMC0_STROBE			0x00000041
			IMX8QXP_EMMC0_RESET_B_CONN_EMMC0_RESET_B	0x00000021		
		>;
	};

	pinctrl_usdhc2_gpio: usdhc2gpiogrp {
		fsl,pins = <
			IMX8QXP_USDHC1_RESET_B_LSIO_GPIO4_IO19     0x00000021
			IMX8QXP_USDHC1_WP_LSIO_GPIO4_IO21          0x00000021
			IMX8QXP_USDHC1_CD_B_LSIO_GPIO4_IO22        0x00000021
		>;
	};


	pinctrl_usdhc2: usdhc2grp {
		fsl,pins = <
			IMX8QXP_USDHC1_CLK_CONN_USDHC1_CLK			0x06000041
			IMX8QXP_USDHC1_CMD_CONN_USDHC1_CMD			0x00000021
			IMX8QXP_USDHC1_DATA0_CONN_USDHC1_DATA0			0x00000021
			IMX8QXP_USDHC1_DATA1_CONN_USDHC1_DATA1			0x00000021
			IMX8QXP_USDHC1_DATA2_CONN_USDHC1_DATA2			0x00000021
			IMX8QXP_USDHC1_DATA3_CONN_USDHC1_DATA3			0x00000021
		>;
	};

	pinctrl_i2c_mipi_csi0: i2c_mipi_csi0 {
		fsl,pins = <
			IMX8QXP_MIPI_CSI0_I2C0_SCL_MIPI_CSI0_I2C0_SCL		0xc2000020
			IMX8QXP_MIPI_CSI0_I2C0_SDA_MIPI_CSI0_I2C0_SDA		0xc2000020
		>;
	};

	pinctrl_mipi_csi0: mipi_csi0 {
		fsl,pins = <
			IMX8QXP_SPI2_SCK_LSIO_GPIO1_IO03	0xC0000041	/* CAM1_PWR# */
			IMX8QXP_SPI2_SDO_LSIO_GPIO1_IO01	0xC0000041	/* CAM1_RST# */
			IMX8QXP_MIPI_CSI0_MCLK_OUT_MIPI_CSI0_ACM_MCLK_OUT	0xC0000041
		>;
	};

	pinctrl_wdt_en_1: wdt_engrp-1 {
		fsl,pins = <
			IMX8QXP_ADC_IN5_LSIO_GPIO1_IO13	0x06000041	/* WDT_EN */
		>;
	};

	pinctrl_wdt_ping_1: wdt_pinggrp-1 {
		fsl,pins = <
			IMX8QXP_ADC_IN4_LSIO_GPIO1_IO14	0x06000041	/* WDOG_TRIG */
		>;
	};

	pinctrl_tpm: tpm_grp {
		fsl,pins = <
			IMX8QXP_QSPI0A_SS1_B_LSIO_GPIO3_IO15	0x06000021	/* TPM_IRQ */
		>;
	};

	pinctrl_usbotg1: usbotg1_grp {
		fsl,pins = <
			IMX8QXP_USB_SS3_TC0_LSIO_GPIO4_IO03	0x00000040	/* USB0_OTG_EN_OC# */
		>;
	};

	pinctrl_usbotg3: usbotg3_grp {
		fsl,pins = <
			IMX8QXP_USB_SS3_TC2_LSIO_GPIO4_IO05	0x00000020	/* USB1_EN_OC# */
		>;
	};

	pinctrl_ldb1: ldb1_grp {
		fsl,pins = <
			IMX8QXP_QSPI0A_DQS_LSIO_GPIO3_IO13		0x00000021	/* LCD0_VDD_EN */
			IMX8QXP_MIPI_CSI0_GPIO0_01_LSIO_GPIO3_IO07	0x00000021	/* LCD0_BKLT_EN */
		>;
	};

	pinctrl_ldb2: ldb2_grp {
		fsl,pins = <
			IMX8QXP_SPDIF0_EXT_CLK_LSIO_GPIO0_IO12	0x00000021	/* LCD1_VDD_EN */
			IMX8QXP_MIPI_CSI0_GPIO0_00_LSIO_GPIO3_IO08	0x00000021	/* LCD1_BKLT_EN */
		>;
	};

	pinctrl_sai_mclk: sai_mclk_grp {
		fsl,pins = <
			IMX8QXP_MCLK_OUT0_ADMA_ACM_MCLK_OUT0	0x00000040	/* AUDIO_MCLK */
		>;
	};

	pinctrl_battery: battery_grp {
		fsl,pins = <
			IMX8QXP_CSI_RESET_LSIO_GPIO3_IO03	0x06000021	/* SMB_ALERT_1V8# */
		>;
	};
};

&watchdog {
	status = "disabled";
};
